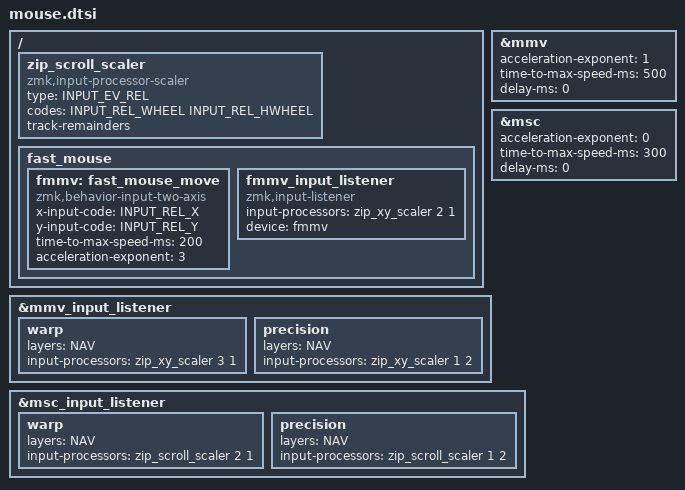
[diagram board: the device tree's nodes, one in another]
#define ZMK_POINTING_DEFAULT_MOVE_VAL 600 // 600
#define ZMK_POINTING_DEFAULT_SCRL_VAL 20  // 10

#include <dt-bindings/zmk/pointing.h>
#include <input/processors.dtsi>
#include <zephyr/dt-bindings/input/input-event-codes.h>

&mmv {
  acceleration-exponent = <1>;          // 1
  time-to-max-speed-ms = <500>;         // 300
  delay-ms = <0>;                       // 0
};


&msc {
  acceleration-exponent = <0>;          // 0
  time-to-max-speed-ms = <300>;         // 300
  delay-ms = <0>;                       // 0
};

&mmv_input_listener {
  warp {
    layers = <NAV>;
    input-processors = <&zip_xy_scaler 3 1>;
  };
  precision {
    layers = <NAV>;
    input-processors = <&zip_xy_scaler 1 2>;
  };
};

/ {
  zip_scroll_scaler: zip_scroll_scaler {
    compatible = "zmk,input-processor-scaler";
    #input-processor-cells = <2>;
    type = <INPUT_EV_REL>;
    codes = <INPUT_REL_WHEEL INPUT_REL_HWHEEL>;
    track-remainders;
  };
};

&msc_input_listener {
  warp {
    layers = <NAV>;
    input-processors = <&zip_scroll_scaler 2 1>;
  };
  precision {
    layers = <NAV>;
    input-processors = <&zip_scroll_scaler 1 2>;
  };
};
/ {
// FAST MOUSE
    fast_mouse {
        /omit-if-no-ref/ fmmv: fast_mouse_move {
            compatible = "zmk,behavior-input-two-axis";
            #binding-cells = <1>;
            x-input-code = <INPUT_REL_X>;
            y-input-code = <INPUT_REL_Y>;
            time-to-max-speed-ms = <200>;
            acceleration-exponent = <3>;
        };
        fmmv_input_listener {
            compatible = "zmk,input-listener";
            input-processors = <&zip_xy_scaler 2 1>;
            device = <&fmmv>;
        };
    };
};
